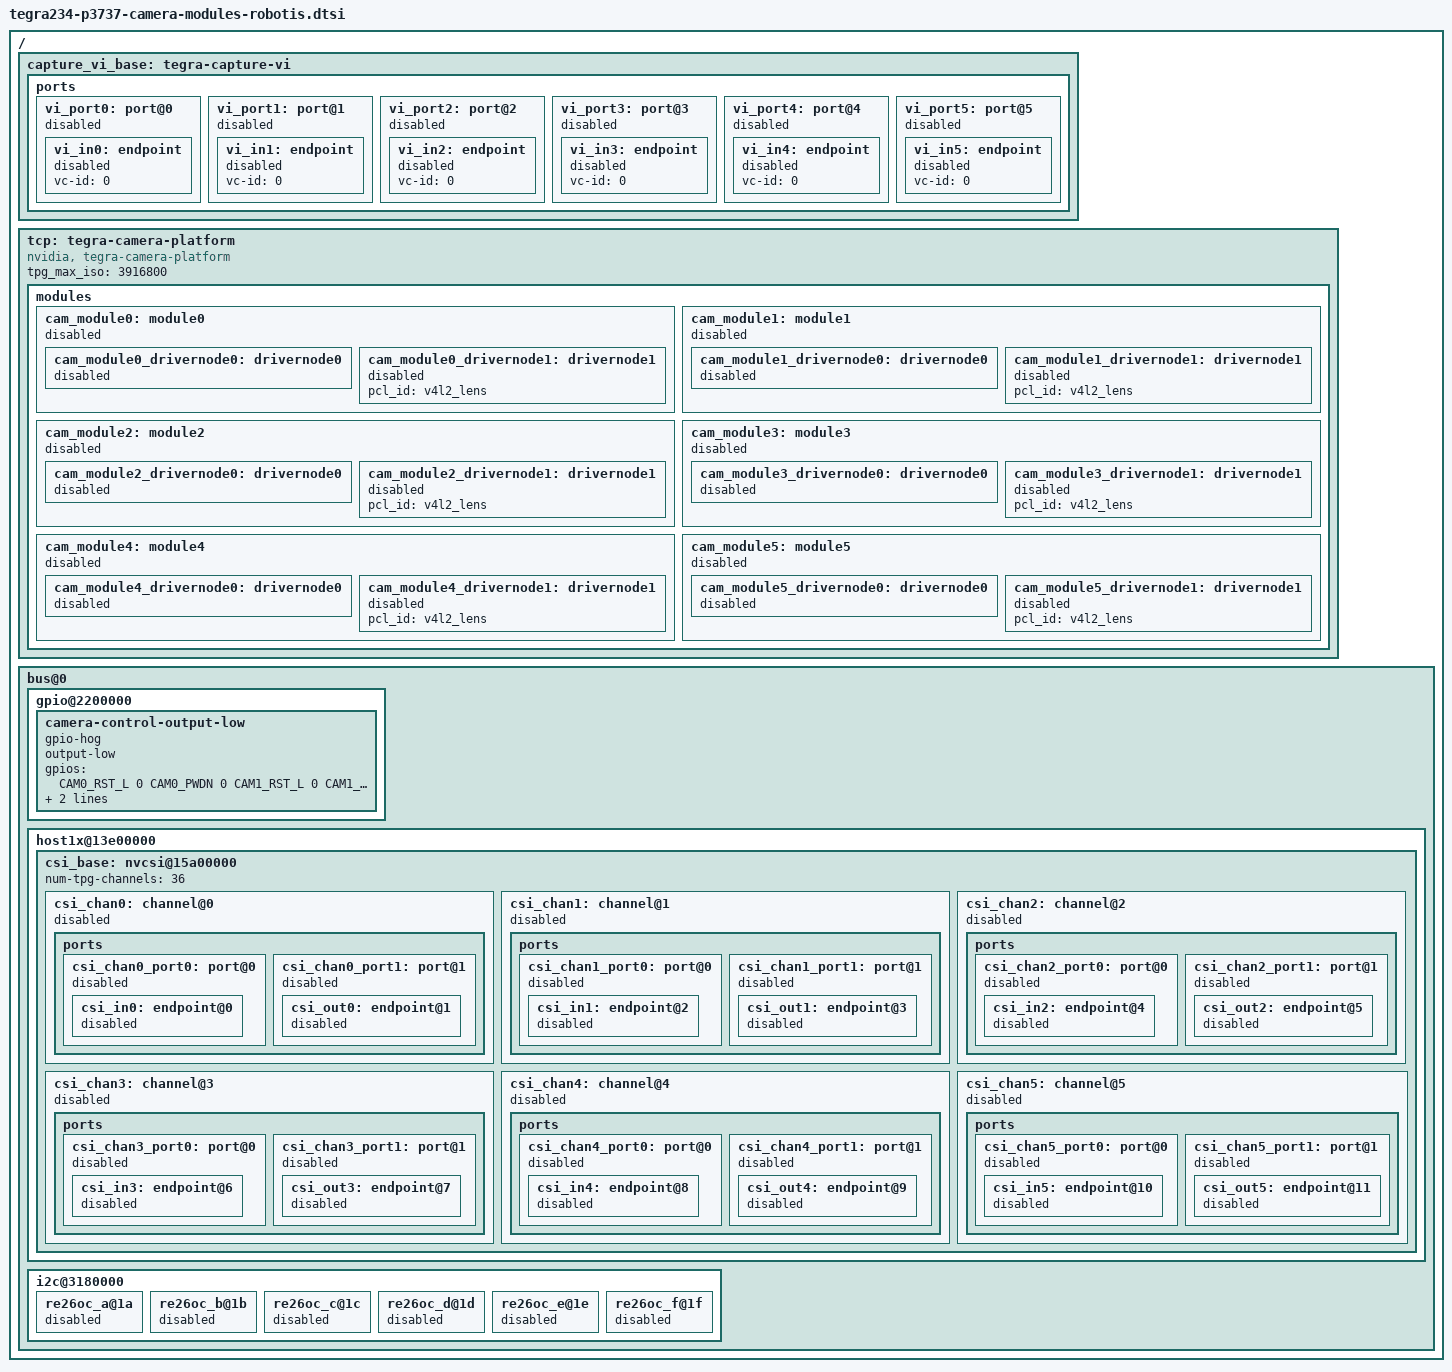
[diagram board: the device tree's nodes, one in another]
// SPDX-License-Identifier: GPL-2.0-only
// SPDX-FileCopyrightText: Copyright (c) 2022-2023, NVIDIA CORPORATION & AFFILIATES. All rights reserved.

//#include "tegra234-camera-e3331-a00.dtsi"
//#include "tegra234-camera-e3333-a00.dtsi"
//#include "tegra234-camera-imx390-a00.dtsi"
//#include "tegra234-camera-ar0234-a00.dtsi"
//#include "tegra234-p3737-0000-camera-imx185-a00.dtsi"
//#include "tegra234-p3737-0000-camera-imx274-dual.dtsi"
#include "tegra234-p3737-0000-camera-re26oc-robotis.dtsi"

#define CAM0_RST_L	TEGRA234_MAIN_GPIO(H, 3)
#define CAM0_PWDN	TEGRA234_MAIN_GPIO(H, 6)
#define CAM1_RST_L	TEGRA234_MAIN_GPIO(AC, 1)
#define CAM1_PWDN	TEGRA234_MAIN_GPIO(AC, 0)

/ {
	fragment-camera-module@0 {
		target-path = "/";
		__overlay__ {
			/* all cameras are disabled by default */
			capture_vi_base: tegra-capture-vi {
				ports {
					vi_port0: port@0 {
						status = "disabled";
						vi_in0: endpoint {
							vc-id = <0>;
							status = "disabled";
						};
					};
					vi_port1: port@1 {
						status = "disabled";
						vi_in1: endpoint {
							vc-id = <0>;
							status = "disabled";
						};
					};
					vi_port2: port@2 {
						status = "disabled";
						vi_in2: endpoint {
							vc-id = <0>;
							status = "disabled";
						};
					};
					vi_port3: port@3 {
						status = "disabled";
						vi_in3: endpoint {
							vc-id = <0>;
							status = "disabled";
						};
					};
					vi_port4: port@4 {
						status = "disabled";
						vi_in4: endpoint {
							vc-id = <0>;
							status = "disabled";
						};
					};
					vi_port5: port@5 {
						status = "disabled";
						vi_in5: endpoint {
							vc-id = <0>;
							status = "disabled";
						};
					};
				};
			};

			tcp: tegra-camera-platform {
				compatible = "nvidia, tegra-camera-platform";
				/**
				* tpg_max_iso = <>;
				* Max iso bw for 6 streams of tpg
				* streams * nvcsi_freq * PG_bitrate / RG10 * BPP
				* 6 * 102Mhz * 32 bits/ 10 bits * 2 Bps
				* = 3916.8 MBps
				*/
				tpg_max_iso = <3916800>;
				modules {
					cam_module0: module0 {
						status = "disabled";
						cam_module0_drivernode0: drivernode0 {
							status = "disabled";
						};
						cam_module0_drivernode1: drivernode1 {
							status = "disabled";
							pcl_id = "v4l2_lens";
						};
					};
					cam_module1: module1 {
						status = "disabled";
						cam_module1_drivernode0: drivernode0 {
							status = "disabled";
						};
						cam_module1_drivernode1: drivernode1 {
							status = "disabled";
							pcl_id = "v4l2_lens";
						};
					};
					cam_module2: module2 {
						status = "disabled";
						cam_module2_drivernode0: drivernode0 {
							status = "disabled";
						};
						cam_module2_drivernode1: drivernode1 {
							status = "disabled";
							pcl_id = "v4l2_lens";
						};
					};
					cam_module3: module3 {
						status = "disabled";
						cam_module3_drivernode0: drivernode0 {
							status = "disabled";
						};
						cam_module3_drivernode1: drivernode1 {
							status = "disabled";
							pcl_id = "v4l2_lens";
						};
					};
					cam_module4: module4 {
						status = "disabled";
						cam_module4_drivernode0: drivernode0 {
							status = "disabled";
						};
						cam_module4_drivernode1: drivernode1 {
							status = "disabled";
							pcl_id = "v4l2_lens";
						};
					};
					cam_module5: module5 {
						status = "disabled";
						cam_module5_drivernode0: drivernode0 {
							status = "disabled";
						};
						cam_module5_drivernode1: drivernode1 {
							status = "disabled";
							pcl_id = "v4l2_lens";
						};
					};
				};
			};

			bus@0 {
				/* set camera gpio direction to output */
				gpio@2200000 {
					camera-control-output-low {
						gpio-hog;
						output-low;
						gpios = <CAM0_RST_L 0 CAM0_PWDN 0
							 CAM1_RST_L 0 CAM1_PWDN 0>;
						label = "cam0-rst", "cam0-pwdn",
							"cam1-rst", "cam1-pwdn";
					};
				};

				host1x@13e00000 {
					csi_base: nvcsi@15a00000 {
						num-tpg-channels = <36>;
						csi_chan0: channel@0 {
							status = "disabled";
							ports {
								csi_chan0_port0: port@0 {
									status = "disabled";
									csi_in0: endpoint@0 {
										status = "disabled";
									};
								};
								csi_chan0_port1: port@1 {
									status = "disabled";
									csi_out0: endpoint@1 {
										status = "disabled";
									};
								};
							};
						};
						csi_chan1: channel@1 {
							status = "disabled";
							ports {
								csi_chan1_port0: port@0 {
									status = "disabled";
									csi_in1: endpoint@2 {
										status = "disabled";
									};
								};
								csi_chan1_port1: port@1 {
									status = "disabled";
									csi_out1: endpoint@3 {
										status = "disabled";
									};
								};
							};
						};
						csi_chan2: channel@2 {
							status = "disabled";
							ports {
								csi_chan2_port0: port@0 {
									status = "disabled";
									csi_in2: endpoint@4 {
										status = "disabled";
									};
								};
								csi_chan2_port1: port@1 {
									status = "disabled";
									csi_out2: endpoint@5 {
										status = "disabled";
									};
								};
							};
						};
						csi_chan3: channel@3 {
							status = "disabled";
							ports {
								csi_chan3_port0: port@0 {
									status = "disabled";
									csi_in3: endpoint@6 {
										status = "disabled";
									};
								};
								csi_chan3_port1: port@1 {
									status = "disabled";
									csi_out3: endpoint@7 {
										status = "disabled";
									};
								};
							};
						};
						csi_chan4: channel@4 {
							status = "disabled";
							ports {
								csi_chan4_port0: port@0 {
									status = "disabled";
									csi_in4: endpoint@8 {
										status = "disabled";
									};
								};
								csi_chan4_port1: port@1 {
									status = "disabled";
									csi_out4: endpoint@9 {
										status = "disabled";
									};
								};
							};
						};
						csi_chan5: channel@5 {
							status = "disabled";
							ports {
								csi_chan5_port0: port@0 {
									status = "disabled";
									csi_in5: endpoint@10 {
										status = "disabled";
									};
								};
								csi_chan5_port1: port@1 {
									status = "disabled";
									csi_out5: endpoint@11 {
										status = "disabled";
									};
								};
							};
						};
					};
				};
				i2c@3180000 {
					re26oc_a@1a {
						status = "disabled";
					};

					re26oc_b@1b {
						status = "disabled";
					};

					re26oc_c@1c {
						status = "disabled";
					};

                                        re26oc_d@1d {
						status = "disabled";
					};

					re26oc_e@1e {
						status = "disabled";
					};

					re26oc_f@1f {
						status = "disabled";
					};
				};
			};
		};
	};
};
